# ATSAMC21N17A register map
Registers are 32-bit, access not given, no defined reset value unless marked. A register's access mark holds for its fields unless they carry their own. Addresses are absolute; registers are grouped by the start of their names; [hi:lo] are bit positions; {n}, {i} and the like mark numbered series; 'fields as' and 'values as' point back to an identical list.

## RTC
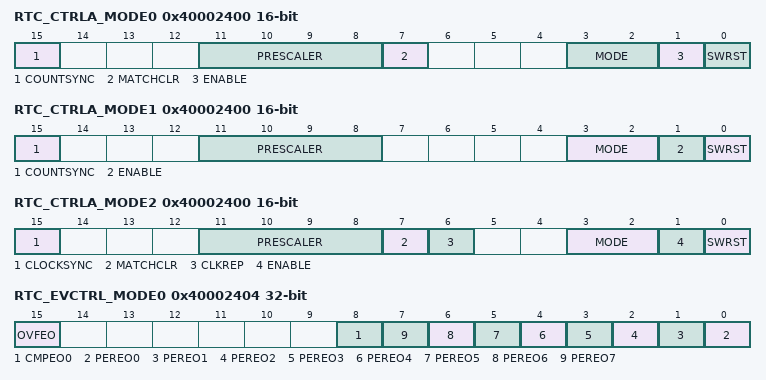
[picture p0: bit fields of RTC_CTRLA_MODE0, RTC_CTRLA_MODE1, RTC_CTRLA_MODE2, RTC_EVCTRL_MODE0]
0x40002400 RTC_CTRLA_MODE0 16-bit — MODE0 Control A
  [15] COUNTSYNC — Count Read Synchronization Enable
  [11:8] PRESCALER
  [7] MATCHCLR — Clear on Match
  [3:2] MODE — Operating Mode
  [1] ENABLE
  [0] SWRST — Software Reset
0x40002400 RTC_CTRLA_MODE1 16-bit — MODE1 Control A
  [15] COUNTSYNC — Count Read Synchronization Enable
  [11:8] PRESCALER
  [3:2] MODE — Operating Mode
  [1] ENABLE
  [0] SWRST — Software Reset
0x40002400 RTC_CTRLA_MODE2 16-bit — MODE2 Control A
  [15] CLOCKSYNC — Clock Read Synchronization Enable
  [11:8] PRESCALER
  [7] MATCHCLR — Clear on Match
  [6] CLKREP — Clock Representation
  [3:2] MODE — Operating Mode
  [1] ENABLE
  [0] SWRST — Software Reset
0x40002404 RTC_EVCTRL_MODE0 — MODE0 Event Control
  [15] OVFEO — Overflow Event Output Enable
  [8] CMPEO0 — Compare 0 Event Output Enable
  [n] PEREO{n} (n=0..7) — Periodic Interval {n} Event Output Enable
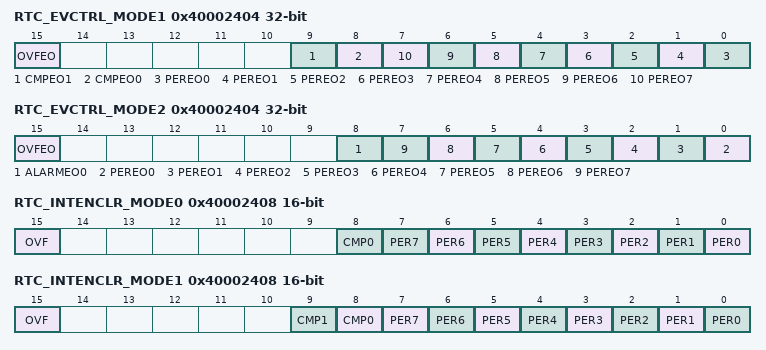
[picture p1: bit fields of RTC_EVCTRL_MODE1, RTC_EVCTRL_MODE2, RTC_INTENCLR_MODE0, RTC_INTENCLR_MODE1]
0x40002404 RTC_EVCTRL_MODE1 — MODE1 Event Control
  [15] OVFEO — Overflow Event Output Enable
  [9] CMPEO1 — Compare 1 Event Output Enable
  [8] CMPEO0 — Compare 0 Event Output Enable
  [n] PEREO{n} (n=0..7) — Periodic Interval {n} Event Output Enable
0x40002404 RTC_EVCTRL_MODE2 — MODE2 Event Control
  [15] OVFEO — Overflow Event Output Enable
  [8] ALARMEO0 — Alarm 0 Event Output Enable
  [n] PEREO{n} (n=0..7) — Periodic Interval {n} Event Output Enable
0x40002408 RTC_INTENCLR_MODE0 16-bit — MODE0 Interrupt Enable Clear
  [15] OVF — Overflow Interrupt Enable
  [8] CMP0 — Compare 0 Interrupt Enable
  [n] PER{n} (n=0..7) — Periodic Interval {n} Interrupt Enable
0x40002408 RTC_INTENCLR_MODE1 16-bit — MODE1 Interrupt Enable Clear
  [15] OVF — Overflow Interrupt Enable
  [9] CMP1 — Compare 1 Interrupt Enable
  [8] CMP0 — Compare 0 Interrupt Enable
  [n] PER{n} (n=0..7) — Periodic Interval {n} Interrupt Enable
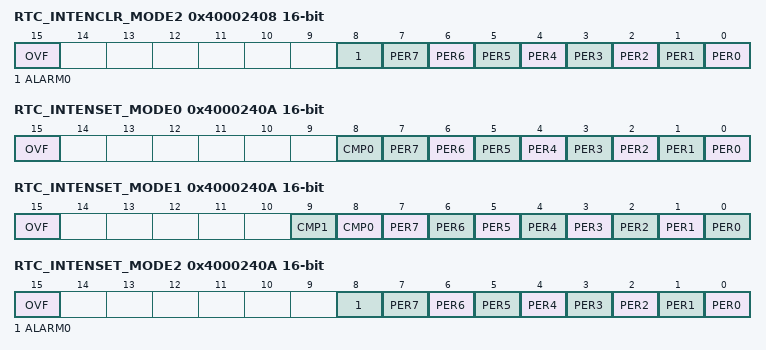
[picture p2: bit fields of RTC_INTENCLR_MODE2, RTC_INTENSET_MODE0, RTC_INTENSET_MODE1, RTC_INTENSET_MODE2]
0x40002408 RTC_INTENCLR_MODE2 16-bit — MODE2 Interrupt Enable Clear
  [15] OVF — Overflow Interrupt Enable
  [8] ALARM0 — Alarm 0 Interrupt Enable
  [n] PER{n} (n=0..7) — Periodic Interval {n} Interrupt Enable
0x4000240A RTC_INTENSET_MODE0 16-bit — MODE0 Interrupt Enable Set
  fields as RTC_INTENCLR_MODE0
0x4000240A RTC_INTENSET_MODE1 16-bit — MODE1 Interrupt Enable Set
  fields as RTC_INTENCLR_MODE1
0x4000240A RTC_INTENSET_MODE2 16-bit — MODE2 Interrupt Enable Set
  [15] OVF — Overflow Interrupt Enable
  [8] ALARM0 — Alarm 0 Interrupt Enable
  [n] PER{n} (n=0..7) — Periodic Interval {n} Enable
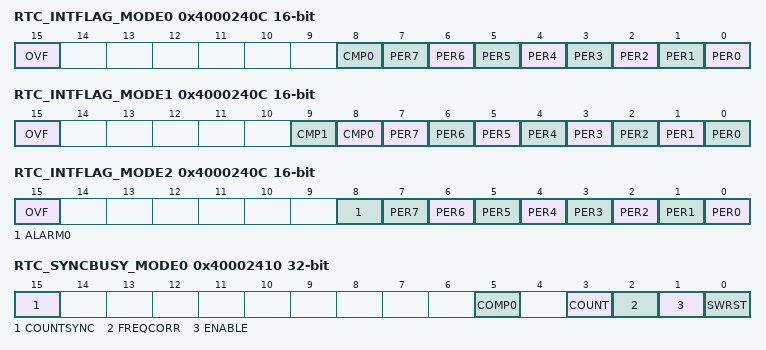
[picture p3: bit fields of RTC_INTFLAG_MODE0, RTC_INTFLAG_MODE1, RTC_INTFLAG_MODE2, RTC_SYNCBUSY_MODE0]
0x4000240C RTC_INTFLAG_MODE0 16-bit — MODE0 Interrupt Flag Status and Clear
  [15] OVF — Overflow
  [8] CMP0 — Compare 0
  [n] PER{n} (n=0..7) — Periodic Interval {n}
0x4000240C RTC_INTFLAG_MODE1 16-bit — MODE1 Interrupt Flag Status and Clear
  [15] OVF — Overflow
  [9] CMP1 — Compare 1
  [8] CMP0 — Compare 0
  [n] PER{n} (n=0..7) — Periodic Interval {n}
0x4000240C RTC_INTFLAG_MODE2 16-bit — MODE2 Interrupt Flag Status and Clear
  [15] OVF — Overflow
  [8] ALARM0
  [n] PER{n} (n=0..7) — Periodic Interval {n}
0x4000240E RTC_DBGCTRL 8-bit — Debug Control
  [0] DBGRUN
0x40002410 RTC_SYNCBUSY_MODE0 — MODE0 Synchronization Busy Status
  [15] COUNTSYNC — Count Read Synchronization Enable Bit Busy
  [5] COMP0 — COMP 0 Register Busy
  [3] COUNT — COUNT Register Busy
  [2] FREQCORR — FREQCORR Register Busy
  [1] ENABLE — Enable Bit Busy
  [0] SWRST — Software Reset Busy
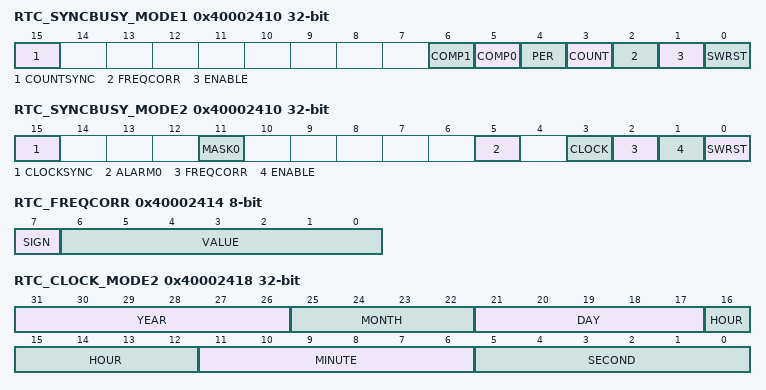
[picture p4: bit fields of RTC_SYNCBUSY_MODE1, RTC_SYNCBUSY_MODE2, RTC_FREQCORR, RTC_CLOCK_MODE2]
0x40002410 RTC_SYNCBUSY_MODE1 — MODE1 Synchronization Busy Status
  [15] COUNTSYNC — Count Read Synchronization Enable Bit Busy
  [6] COMP1 — COMP 1 Register Busy
  [5] COMP0 — COMP 0 Register Busy
  [4] PER — PER Register Busy
  [3] COUNT — COUNT Register Busy
  [2] FREQCORR — FREQCORR Register Busy
  [1] ENABLE — Enable Bit Busy
  [0] SWRST — Software Reset Bit Busy
0x40002410 RTC_SYNCBUSY_MODE2 — MODE2 Synchronization Busy Status
  [15] CLOCKSYNC — Clock Read Synchronization Enable Bit Busy
  [11] MASK0 — MASK 0 Register Busy
  [5] ALARM0 — ALARM 0 Register Busy
  [3] CLOCK — CLOCK Register Busy
  [2] FREQCORR — FREQCORR Register Busy
  [1] ENABLE — Enable Bit Busy
  [0] SWRST — Software Reset Bit Busy
0x40002414 RTC_FREQCORR 8-bit — Frequency Correction
  [7] SIGN, [6:0] VALUE
0x40002418 RTC_COUNT_MODE0 — MODE0 Counter Value
  [31:0] COUNT — Counter Value
0x40002418 RTC_COUNT_MODE1 16-bit — MODE1 Counter Value
  [15:0] COUNT — Counter Value
0x40002418 RTC_CLOCK_MODE2 — MODE2 Clock Value
  [31:26] YEAR, [25:22] MONTH, [21:17] DAY, [16:12] HOUR, [11:6] MINUTE, [5:0] SECOND
0x4000241C RTC_PER_MODE1 16-bit — MODE1 Counter Period
  [15:0] PER — Counter Period
0x40002420 RTC_COMP_MODE0 — MODE0 Compare n Value
  [31:0] COMP — Compare Value
0x40002420 RTC_COMP_MODE1 16-bit — MODE1 Compare n Value
  [15:0] COMP — Compare Value
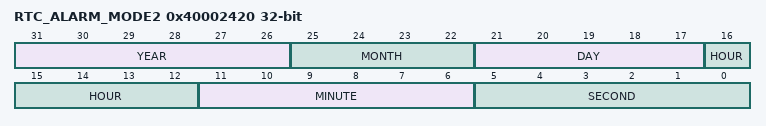
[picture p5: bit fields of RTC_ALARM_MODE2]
0x40002420 RTC_ALARM_MODE2 — MODE2_ALARM Alarm n Value
  fields as RTC_CLOCK_MODE2
0x40002424 RTC_MASK_MODE2 8-bit — MODE2_ALARM Alarm n Mask
  [2:0] SEL — Alarm Mask Selection
